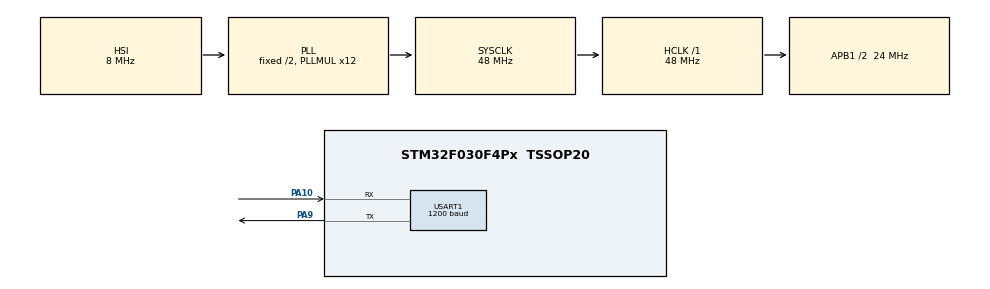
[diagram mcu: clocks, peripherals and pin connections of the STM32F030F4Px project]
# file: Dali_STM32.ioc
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Dma.Request0=USART1_RX
Dma.USART1_RX.0.Direction=DMA_PERIPH_TO_MEMORY
Dma.USART1_RX.0.Instance=DMA1_Channel3
Dma.USART1_RX.0.MemDataAlignment=DMA_MDATAALIGN_BYTE
Dma.USART1_RX.0.MemInc=DMA_MINC_ENABLE
Dma.USART1_RX.0.Mode=DMA_NORMAL
Dma.USART1_RX.0.PeriphDataAlignment=DMA_PDATAALIGN_BYTE
Dma.USART1_RX.0.PeriphInc=DMA_PINC_DISABLE
Dma.USART1_RX.0.Priority=DMA_PRIORITY_MEDIUM
Mcu.Family=STM32F0
Mcu.Name=STM32F030F4Px
Mcu.Package=TSSOP20
NVIC.DMA1_Channel2_3_IRQn=true\:0\:0\:false\:false\:true\:false\:true\:true
NVIC.USART1_IRQn=true\:0\:0\:false\:false\:true\:true\:true\:true
PA10.GPIO_FMA10=__NULL
PA10.GPIO_ModeDefaultPP=GPIO_MODE_AF_PP
PA10.Mode=Asynchronous
PA10.Signal=USART1_RX
PA13.Mode=Serial_Wire
PA13.Signal=SYS_SWDIO
PA14.Mode=Serial_Wire
PA14.Signal=SYS_SWCLK
PA9.GPIO_FMA9=__NULL
PA9.GPIO_ModeDefaultPP=GPIO_MODE_AF_PP
PA9.GPIO_PuPd=GPIO_NOPULL
PA9.Mode=Asynchronous
PA9.Signal=USART1_TX
ProjectManager.HeapSize=0x200
ProjectManager.StackSize=0x400
ProjectManager.TargetToolchain=Makefile
RCC.AHBFreq_Value=48000000
RCC.APB1CLKDivider=RCC_HCLK_DIV2
RCC.APB1Freq_Value=24000000
RCC.APB1TimFreq_Value=48000000
RCC.HCLKFreq_Value=48000000
RCC.HSE_Timout=100
RCC.PLLMUL=RCC_PLL_MUL12
RCC.SYSCLKFreq_VALUE=48000000
RCC.SYSCLKSource=RCC_SYSCLKSOURCE_PLLCLK
USART1.BaudRate=1200
USART1.OneBitSampling=UART_ONE_BIT_SAMPLE_DISABLE
USART1.OverSampling=UART_OVERSAMPLING_8
USART1.VirtualMode-Asynchronous=VM_ASYNC
board=custom

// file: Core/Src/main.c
/* USER CODE BEGIN Header */
/**
 ******************************************************************************
 * @file           : main.c
 * @brief          : Main program body
 ******************************************************************************
 * @attention
 *
 * Copyright (c) 2025 STMicroelectronics.
 * All rights reserved.
 *
 * This software is licensed under terms that can be found in the LICENSE file
 * in the root directory of this software component.
 * If no LICENSE file comes with this software, it is provided AS-IS.
 *
 ******************************************************************************
 */
/* USER CODE END Header */
#include "main.h"
#include "dma.h"
#include "usart.h"
#include "gpio.h"

/* USER CODE BEGIN Includes */
#include <string.h>
/* USER CODE END Includes */

/* USER CODE BEGIN PD */
#define RX_BUFFER_SIZE 10
/* USER CODE END PD */

/* USER CODE BEGIN PV */
uint8_t rxBuffer[RX_BUFFER_SIZE];
volatile uint8_t dataReceived = 0;
/* USER CODE END PV */

void SystemClock_Config(void);

int main(void)
{

  /* MCU Configuration--------------------------------------------------------*/

  /* Reset of all peripherals, Initializes the Flash interface and the Systick. */
  HAL_Init();

  /* Configure the system clock */
  SystemClock_Config();

  /* Initialize all configured peripherals */
  MX_GPIO_Init();
  MX_DMA_Init();
  MX_USART1_UART_Init();
  /* USER CODE BEGIN 2 */
  const char *str_tx = "hello ";
  memset(rxBuffer, 0, RX_BUFFER_SIZE);

  // Сброс флагов ошибок UART перед началом работы
  __HAL_UART_CLEAR_OREFLAG(&huart1);
  __HAL_UART_CLEAR_FEFLAG(&huart1);
  __HAL_UART_CLEAR_NEFLAG(&huart1);
  __HAL_UART_CLEAR_PEFLAG(&huart1);

  if (HAL_UARTEx_ReceiveToIdle_DMA(&huart1, rxBuffer, RX_BUFFER_SIZE) != HAL_OK)
  {
    Error_Handler();
  }
  // Отключаем Half‑Transfer Interrupt (HT), чтобы игнорировать событие заполнения половины буфера
  __HAL_DMA_DISABLE_IT(huart1.hdmarx, DMA_IT_HT);
  /* USER CODE END 2 */

  /* Infinite loop */
  while (1)
  {

    /* USER CODE BEGIN 3 */
    /* передаём строку */
    if (HAL_UART_Transmit(&huart1, (uint8_t *)str_tx, strlen(str_tx), 100) != HAL_OK)
    {
      /* ошибка при передаче */
      Error_Handler();
    }

    /* пауза 1 секунду перед следующей отправкой */
    HAL_Delay(2000);
  }
  /* USER CODE END 3 */
}

void SystemClock_Config(void)
{
  RCC_OscInitTypeDef RCC_OscInitStruct = {0};
  RCC_ClkInitTypeDef RCC_ClkInitStruct = {0};
  RCC_PeriphCLKInitTypeDef PeriphClkInit = {0};

  /** Initializes the RCC Oscillators according to the specified parameters
   * in the RCC_OscInitTypeDef structure.
   */
  RCC_OscInitStruct.OscillatorType = RCC_OSCILLATORTYPE_HSI;
  RCC_OscInitStruct.HSIState = RCC_HSI_ON;
  RCC_OscInitStruct.HSICalibrationValue = RCC_HSICALIBRATION_DEFAULT;
  RCC_OscInitStruct.PLL.PLLState = RCC_PLL_ON;
  RCC_OscInitStruct.PLL.PLLSource = RCC_PLLSOURCE_HSI;
  RCC_OscInitStruct.PLL.PLLMUL = RCC_PLL_MUL12;
  RCC_OscInitStruct.PLL.PREDIV = RCC_PREDIV_DIV1;
  if (HAL_RCC_OscConfig(&RCC_OscInitStruct) != HAL_OK)
  {
    Error_Handler();
  }

  /** Initializes the CPU, AHB and APB buses clocks
   */
  RCC_ClkInitStruct.ClockType = RCC_CLOCKTYPE_HCLK | RCC_CLOCKTYPE_SYSCLK | RCC_CLOCKTYPE_PCLK1;
  RCC_ClkInitStruct.SYSCLKSource = RCC_SYSCLKSOURCE_PLLCLK;
  RCC_ClkInitStruct.AHBCLKDivider = RCC_SYSCLK_DIV1;
  RCC_ClkInitStruct.APB1CLKDivider = RCC_HCLK_DIV2;

  if (HAL_RCC_ClockConfig(&RCC_ClkInitStruct, FLASH_LATENCY_1) != HAL_OK)
  {
    Error_Handler();
  }
  PeriphClkInit.PeriphClockSelection = RCC_PERIPHCLK_USART1;
  PeriphClkInit.Usart1ClockSelection = RCC_USART1CLKSOURCE_PCLK1;
  if (HAL_RCCEx_PeriphCLKConfig(&PeriphClkInit) != HAL_OK)
  {
    Error_Handler();
  }
}

/* USER CODE BEGIN 4 */
void HAL_UARTEx_RxEventCallback(UART_HandleTypeDef *huart, uint16_t size)
{
  if (huart->Instance == USART1)
  {
    dataReceived = 1;
    HAL_UART_Transmit(&huart1, rxBuffer, size, 200);

    // Перезапуск приёма
    if (HAL_UARTEx_ReceiveToIdle_DMA(huart, rxBuffer, RX_BUFFER_SIZE) != HAL_OK)
    {
      // Если не удалось запустить приём — обработать ошибку
      Error_Handler();
    }
    // Снова отключаем прерывание HT
    __HAL_DMA_DISABLE_IT(huart->hdmarx, DMA_IT_HT);
  }
}

void HAL_UART_ErrorCallback(UART_HandleTypeDef *huart)
{
  if (huart->ErrorCode & HAL_UART_ERROR_ORE)
  {
    // Абортируем DMA-приём — аппаратно выключаем канал, чтобы он не успел записать следующий байт
    if (HAL_DMA_Abort(huart->hdmarx) != HAL_OK)
    {
      Error_Handler();
    }
    // Дожидаемся, пока DMA действительно станет READY
    while (huart->hdmarx->State != HAL_DMA_STATE_READY)
    { /* wait */
    }

    // «Выгружаем» лишний байт из DR: читаем ISR и затем RDR
    __IO uint32_t tmp;
    tmp = huart->Instance->ISR;
    tmp = huart->Instance->RDR;
    (void)tmp;

    // Сбрасываем флаг переполнения
    __HAL_UART_CLEAR_OREFLAG(huart);
  }

  // Перезапускаем приём по DMA
  if (HAL_UARTEx_ReceiveToIdle_DMA(huart, rxBuffer, RX_BUFFER_SIZE) != HAL_OK)
  {
    Error_Handler();
  }
  // По-прежнему отключаем Half-Transfer interrupt
  __HAL_DMA_DISABLE_IT(huart->hdmarx, DMA_IT_HT);
}

/* USER CODE END 4 */

void Error_Handler(void)
{
  /* USER CODE BEGIN Error_Handler_Debug */
  /* User can add his own implementation to report the HAL error return state */
  __disable_irq();
  while (1)
  {
    HAL_Delay(1000);
  }
  /* USER CODE END Error_Handler_Debug */
}
